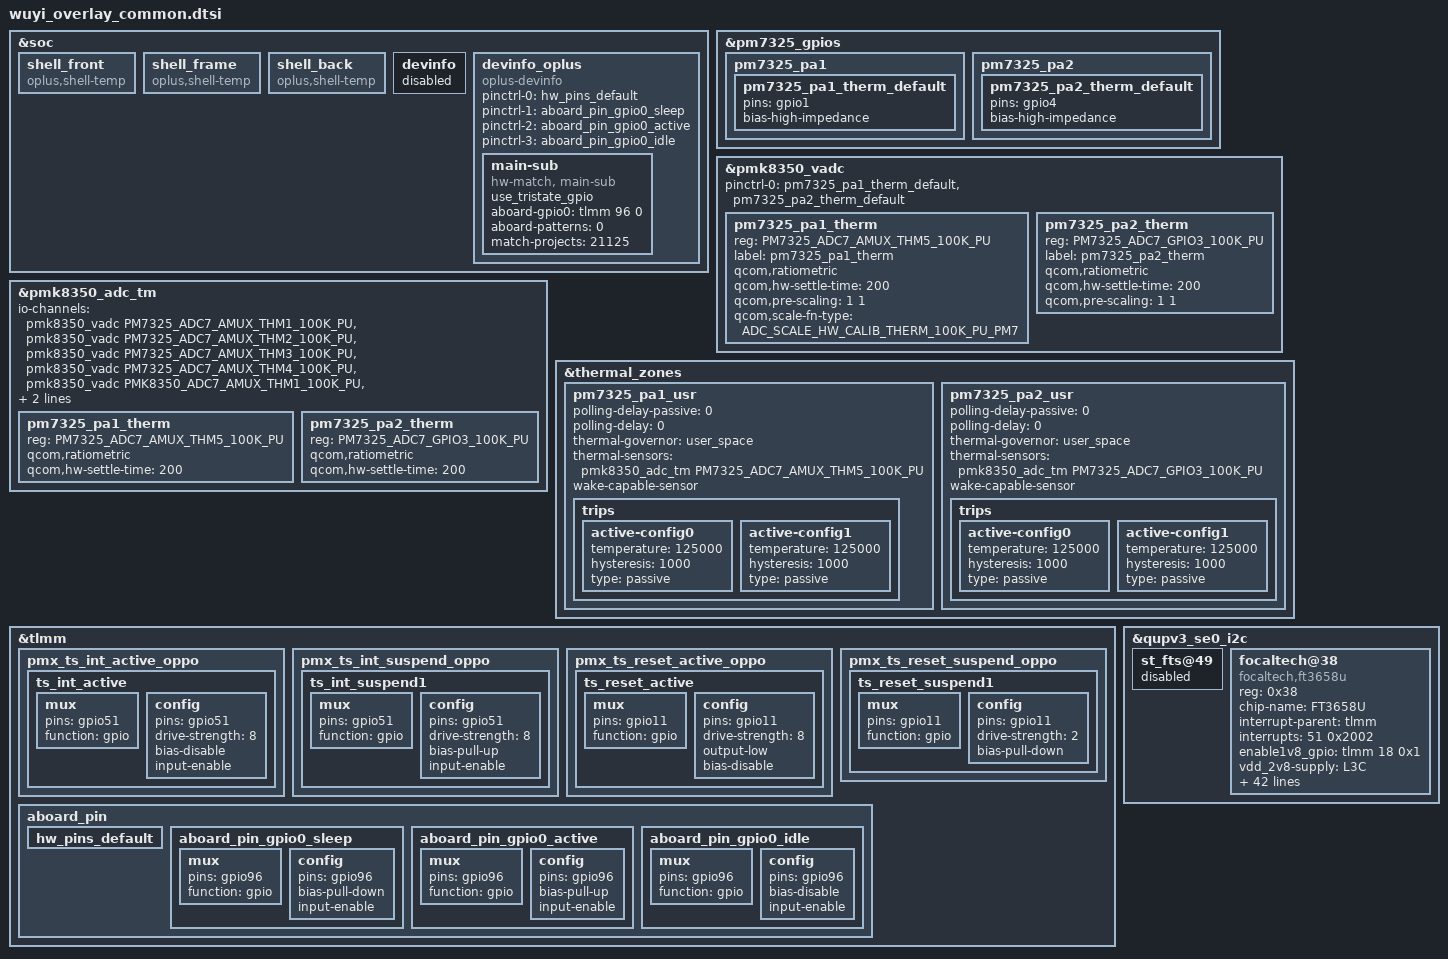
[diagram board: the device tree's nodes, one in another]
/*#ifdef OPLUS_FEATURE_THERMAL*/
#include <dt-bindings/iio/qcom,spmi-vadc.h>
&soc {
	//#ifdef OPLUS_FEATURE_THERMAL_HORAE
	shell_front {
			compatible = "oplus,shell-temp";
	};

	shell_frame {
			compatible = "oplus,shell-temp";
	};

	shell_back {
			compatible = "oplus,shell-temp";
	};
	//#endif

};

&pm7325_gpios {
	pm7325_pa1 {
		pm7325_pa1_therm_default: pm7325_pa1_therm_default {
			pins = "gpio1";
			bias-high-impedance;
		};
	};
	pm7325_pa2 {
                pm7325_pa2_therm_default: pm7325_pa2_therm_default {
                        pins = "gpio4";
                        bias-high-impedance;
                };
        };
};

&pmk8350_vadc {
    pinctrl-names = "default";
	pinctrl-0 = <&pm7325_pa1_therm_default &pm7325_pa2_therm_default>;
	pm7325_pa1_therm {
		reg = <PM7325_ADC7_AMUX_THM5_100K_PU>;
                label = "pm7325_pa1_therm";
                qcom,ratiometric;
                qcom,hw-settle-time = <200>;
                qcom,pre-scaling = <1 1>;
		qcom,scale-fn-type = <ADC_SCALE_HW_CALIB_THERM_100K_PU_PM7>;
	};

	pm7325_pa2_therm {
                reg = <PM7325_ADC7_GPIO3_100K_PU>;
                label = "pm7325_pa2_therm";
                qcom,ratiometric;
                qcom,hw-settle-time = <200>;
                qcom,pre-scaling = <1 1>;
        };
};

&pmk8350_adc_tm {
        io-channels = <&pmk8350_vadc PM7325_ADC7_AMUX_THM1_100K_PU>,
                        <&pmk8350_vadc PM7325_ADC7_AMUX_THM2_100K_PU>,
                        <&pmk8350_vadc PM7325_ADC7_AMUX_THM3_100K_PU>,
                        <&pmk8350_vadc PM7325_ADC7_AMUX_THM4_100K_PU>,
                        <&pmk8350_vadc PMK8350_ADC7_AMUX_THM1_100K_PU>,
                        <&pmk8350_vadc PM7325_ADC7_AMUX_THM5_100K_PU>,
                        <&pmk8350_vadc PM7325_ADC7_GPIO3_100K_PU>;

	pm7325_pa1_therm {
                reg = <PM7325_ADC7_AMUX_THM5_100K_PU>;
                qcom,ratiometric;
                qcom,hw-settle-time = <200>;
        };

	pm7325_pa2_therm {
                reg = <PM7325_ADC7_GPIO3_100K_PU>;
                qcom,ratiometric;
                qcom,hw-settle-time = <200>;
        };
};

&thermal_zones {
	pm7325_pa1_usr {
                polling-delay-passive = <0>;
                polling-delay = <0>;
                thermal-governor = "user_space";
                thermal-sensors = <&pmk8350_adc_tm PM7325_ADC7_AMUX_THM5_100K_PU>;
                wake-capable-sensor;
                trips {
                        active-config0 {
                                temperature = <125000>;
                                hysteresis = <1000>;
                                type = "passive";
                        };

                        active-config1 {
                                temperature = <125000>;
                                hysteresis = <1000>;
                                type = "passive";
                        };
                };
        };

	pm7325_pa2_usr {
                polling-delay-passive = <0>;
                polling-delay = <0>;
                thermal-governor = "user_space";
                thermal-sensors = <&pmk8350_adc_tm PM7325_ADC7_GPIO3_100K_PU>;
                wake-capable-sensor;
                trips {
                        active-config0 {
                                temperature = <125000>;
                                hysteresis = <1000>;
                                type = "passive";
                        };

                        active-config1 {
                                temperature = <125000>;
                                hysteresis = <1000>;
                                type = "passive";
                        };
                };
        };
};
//#endif OPLUS_FEATURE_THERMAL

/*#ifdef OPLUS_FEATURE_TP_BASIC*/

&tlmm {
	/*#ifdef OPLUS_FEATURE_TP_BASIC*/
	pmx_ts_int_active_oppo {
		ts_int_active: ts_int_active {
			mux {
				pins = "gpio51";
				function = "gpio";
			};

			config {
				pins = "gpio51";
				drive-strength = <8>;
				bias-disable;
				input-enable;
			};
		};
	};

	pmx_ts_int_suspend_oppo {
		ts_int_suspend1: ts_int_suspend1 {
			mux {
				pins = "gpio51";
				function = "gpio";
			};

			config {
				pins = "gpio51";
				drive-strength = <8>;
				//bias-pull-down;
				bias-pull-up;
				input-enable;
			};
		};
	};

	pmx_ts_reset_active_oppo {
		ts_reset_active: ts_reset_active {
			mux {
				pins = "gpio11";
				function = "gpio";
			};

			config {
				pins = "gpio11";
				drive-strength = <8>;
				output-low;
				bias-disable;
			};
		};
	};

	pmx_ts_reset_suspend_oppo {
		ts_reset_suspend1: ts_reset_suspend1 {
			mux {
				pins = "gpio11";
				function = "gpio";
			};

			config {
				pins = "gpio11";
				drive-strength = <2>;
				bias-pull-down;
			};
		};
	};

	aboard_pin {
		hw_pins_default:hw_pins_default {
		};

		aboard_pin_gpio0_sleep:aboard_pin_gpio0_sleep {
			mux {
				pins = "gpio96";
				function = "gpio";
			};

			config {
				pins = "gpio96";
				bias-pull-down;
				input-enable;
			};
		};

		aboard_pin_gpio0_active:aboard_pin_gpio0_active {
			mux {
				pins = "gpio96";
				function = "gpio";
			};

			config {
				pins = "gpio96";
				bias-pull-up;
				input-enable;
			};
		};

		aboard_pin_gpio0_idle:aboard_pin_gpio0_idle {
			mux {
				pins = "gpio96";
				function = "gpio";
			};

			config {
				pins = "gpio96";
				bias-disable;
				input-enable;
			};
		};
	};
	/*#endif OPLUS_FEATURE_TP_BASIC*/
};

&soc {
	devinfo {
		status = "disabled";
	};

	devinfo_oplus {
		compatible = "oplus-devinfo";

		pinctrl-names = "default", "sleep", "active", "idle";
		pinctrl-0 = <&hw_pins_default>;
		pinctrl-1 = <&aboard_pin_gpio0_sleep>;
		pinctrl-2 = <&aboard_pin_gpio0_active>;
		pinctrl-3 = <&aboard_pin_gpio0_idle>;

		main-sub {
			compatible = "hw-match, main-sub";
			use_tristate_gpio;
			aboard-gpio0 = <&tlmm 96 0>;
			aboard-patterns = <0>;	/*0[high-resistance] 1[pull-down] 2[pull-up]*/
			/*main board*/
			match-projects = <21125>;
		};
	};
};

&qupv3_se0_i2c {
	status = "okay";

	st_fts@49 {
		status = "disabled";
	};
	focaltech@38 {
		status = "okay";
		compatible = "focaltech,ft3658u";
		reg = <0x38>;
		chip-name = "FT3658U";

		/* Interrupt && Irq-gpio */
		interrupt-parent = <&tlmm>;
		interrupts = <51 0x2002>;

		/* Power Config */
		enable1v8_gpio = <&tlmm 18 0x1>;
		vdd_2v8-supply = <&L3C>;
		vdd_2v8_volt = <3008000>;

		/* Interrupt && Irq-gpio */
		/* Other HW Resource */
		irq-gpio = <&tlmm 51 0x2002>;
		reset-gpio = <&tlmm 11 0x1>;
		pinctrl-names = "default";
		pinctrl-0 = <&ts_int_active &ts_reset_active>;

		touchpanel,max-num-support = <10>;
		touchpanel,tx-rx-num = <16 35>;
		touchpanel,panel-coords = <8640 19200>;
		touchpanel,display-coords = <1080 2400>;
		touchpanel,touchmajor-limit = <0 54>;
		touchpanel,smooth-level = <255 15 40 80 160 240>;
		touchpanel,sensitive-level = <255 30 25 20 10 8>;
                touchpanel,high-frame-rate-time = <20>;
                touchpanel,single-optimized-time = <8>;

		vid_len = <2>;
		project_id = <21125>;
		tp_type = <8>;
		panel_type = <8>;
		firmware_name = "0xAA29800";
		platform_support_project = <21125>;
		platform_support_project_dir = <21125>;
		platform_support_project_commandline = "default_commandline";
		/* SW Support Feature Control */

		irq_need_dev_resume_ok;
		black_gesture_support;
		fw_edge_limit_support;
		pressure_report_support;
		charger_pump_support;
		game_switch_support;
		smart_gesture_support;
		headset_pump_support;
		fw_update_app_support;
		health_monitor_support;
		fingerprint_underscreen_support;
		black_gesture_indep_support;
		//esd_handle_support;
		new_set_irq_wake_support;
		// focalt x8 resolution config
		high_resolution_support;
		high_resolution_support_x8;
                switch_game_rate_support;
		report_rate_game_value = <1>;
		touchpanel,button-type = <4>;
		touchpanel.button-TRx = <0 0>;
		disable_suspend_irq_handler_support;
	};
};
/*#endif OPLUS_FEATURE_TP_BASIC*/
